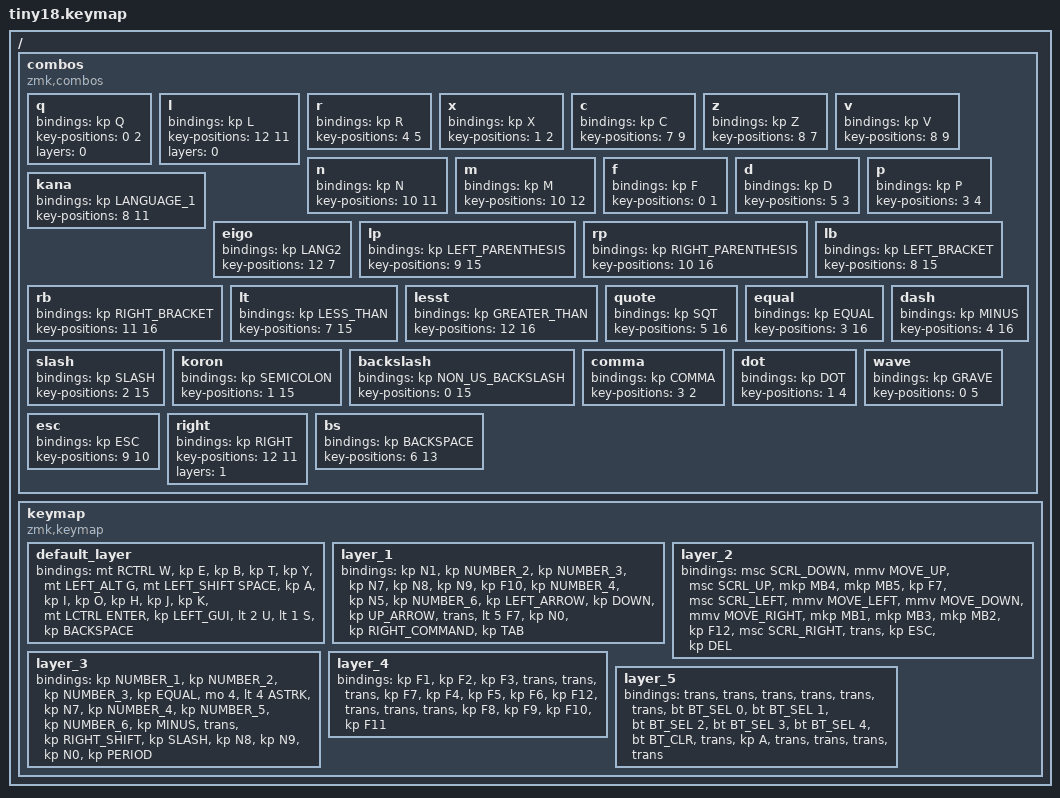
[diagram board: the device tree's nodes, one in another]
#include <input/processors.dtsi>
#include <dt-bindings/zmk/input_transform.h>
#include <zephyr/dt-bindings/input/input-event-codes.h>
#include <behaviors.dtsi>
#include <dt-bindings/zmk/bt.h>
#include <dt-bindings/zmk/keys.h>
#include <dt-bindings/zmk/pointing.h>

/ {
    combos {
        compatible = "zmk,combos";

        q {
            bindings = <&kp Q>;
            key-positions = <0 2>;
            layers = <0>;
        };

        l {
            bindings = <&kp L>;
            key-positions = <12 11>;
            layers = <0>;
        };

        r {
            bindings = <&kp R>;
            key-positions = <4 5>;
        };

        x {
            bindings = <&kp X>;
            key-positions = <1 2>;
        };

        c {
            bindings = <&kp C>;
            key-positions = <7 9>;
        };

        z {
            bindings = <&kp Z>;
            key-positions = <8 7>;
        };

        v {
            bindings = <&kp V>;
            key-positions = <8 9>;
        };

        n {
            bindings = <&kp N>;
            key-positions = <10 11>;
        };

        m {
            bindings = <&kp M>;
            key-positions = <10 12>;
        };

        f {
            bindings = <&kp F>;
            key-positions = <0 1>;
        };

        d {
            bindings = <&kp D>;
            key-positions = <5 3>;
        };

        p {
            bindings = <&kp P>;
            key-positions = <3 4>;
        };

        kana {
            bindings = <&kp LANGUAGE_1>;
            key-positions = <8 11>;
        };

        eigo {
            bindings = <&kp LANG2>;
            key-positions = <12 7>;
        };

        lp {
            bindings = <&kp LEFT_PARENTHESIS>;
            key-positions = <9 15>;
        };

        rp {
            bindings = <&kp RIGHT_PARENTHESIS>;
            key-positions = <10 16>;
        };

        lb {
            bindings = <&kp LEFT_BRACKET>;
            key-positions = <8 15>;
        };

        rb {
            bindings = <&kp RIGHT_BRACKET>;
            key-positions = <11 16>;
        };

        lt {
            bindings = <&kp LESS_THAN>;
            key-positions = <7 15>;
        };

        lesst {
            bindings = <&kp GREATER_THAN>;
            key-positions = <12 16>;
        };

        quote {
            bindings = <&kp SQT>;
            key-positions = <5 16>;
        };

        equal {
            bindings = <&kp EQUAL>;
            key-positions = <3 16>;
        };

        dash {
            bindings = <&kp MINUS>;
            key-positions = <4 16>;
        };

        slash {
            bindings = <&kp SLASH>;
            key-positions = <2 15>;
        };

        koron {
            bindings = <&kp SEMICOLON>;
            key-positions = <1 15>;
        };

        backslash {
            bindings = <&kp NON_US_BACKSLASH>;
            key-positions = <0 15>;
        };

        comma {
            bindings = <&kp COMMA>;
            key-positions = <3 2>;
        };

        dot {
            bindings = <&kp DOT>;
            key-positions = <1 4>;
        };

        wave {
            bindings = <&kp GRAVE>;
            key-positions = <0 5>;
        };

        esc {
            bindings = <&kp ESC>;
            key-positions = <9 10>;
        };

        right {
            bindings = <&kp RIGHT>;
            key-positions = <12 11>;
            layers = <1>;
        };

        bs {
            bindings = <&kp BACKSPACE>;
            key-positions = <6 13>;
        };
    };

    keymap {
        compatible = "zmk,keymap";

        default_layer {
            bindings = <
&mt RCTRL W  &kp E  &kp B  &kp T  &kp Y  &mt LEFT_ALT G  &mt LEFT_SHIFT SPACE  &kp A  &kp I  &kp O  &kp H  &kp J  &kp K  &mt LCTRL ENTER  &kp LEFT_GUI  &lt 2 U  &lt 1 S  &kp BACKSPACE
            >;
        };

        layer_1 {
            bindings = <
&kp N1  &kp NUMBER_2  &kp NUMBER_3  &kp N7  &kp N8  &kp N9  &kp F10  &kp NUMBER_4  &kp N5  &kp NUMBER_6  &kp LEFT_ARROW  &kp DOWN  &kp UP_ARROW  &trans  &lt 5 F7  &kp N0  &kp RIGHT_COMMAND  &kp TAB
            >;
        };

        layer_2 {
            bindings = <
&msc SCRL_DOWN  &mmv MOVE_UP  &msc SCRL_UP  &mkp MB4  &mkp MB5  &kp F7  &msc SCRL_LEFT  &mmv MOVE_LEFT  &mmv MOVE_DOWN  &mmv MOVE_RIGHT  &mkp MB1  &mkp MB3  &mkp MB2  &kp F12  &msc SCRL_RIGHT  &trans  &kp ESC  &kp DEL
            >;
        };

        layer_3 {
            bindings = <
&kp NUMBER_1  &kp NUMBER_2  &kp NUMBER_3  &kp EQUAL  &mo 4  &lt 4 ASTRK  &kp N7  &kp NUMBER_4  &kp NUMBER_5  &kp NUMBER_6  &kp MINUS  &trans  &kp RIGHT_SHIFT  &kp SLASH  &kp N8  &kp N9  &kp N0  &kp PERIOD
            >;
        };

        layer_4 {
            bindings = <
&kp F1  &kp F2  &kp F3  &trans  &trans  &trans  &kp F7  &kp F4  &kp F5  &kp F6  &kp F12  &trans  &trans  &trans  &kp F8  &kp F9  &kp F10  &kp F11
            >;
        };

        layer_5 {
            bindings = <
&trans  &trans  &trans  &trans  &trans  &trans  &bt BT_SEL 0  &bt BT_SEL 1  &bt BT_SEL 2  &bt BT_SEL 3  &bt BT_SEL 4  &bt BT_CLR  &trans  &kp A  &trans  &trans  &trans  &trans
            >;
        };
    };
};
